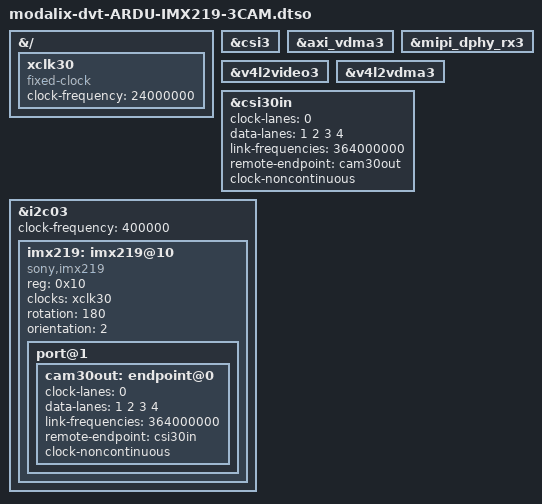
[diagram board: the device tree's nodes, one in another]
// SPDX-License-Identifier: (GPL-2.0+ OR MIT)
/*
 * Copyright (c) 2026 SiMa ai
 */

/dts-v1/;
/plugin/;

&{/} {
        xclk30: xclk30 {
                status = "okay";
                compatible = "fixed-clock";
                #clock-cells = <0>;
                clock-frequency = <24000000>;
        };
};

&csi3 {
    status = "okay";
};

&axi_vdma3 {
    status = "okay";
};

&mipi_dphy_rx3 {
    status = "okay";
};

&v4l2video3 {
    status = "okay";
};

&v4l2vdma3 {
    status = "okay";
};

&csi30in{
    clock-lanes = <0>;
    data-lanes = <1 2 3 4>;
    link-frequencies = /bits/ 64 <364000000>;
    remote-endpoint = <&cam30out>;
    clock-noncontinuous;
};

&i2c03 {
        status = "okay";
        clock-frequency = <400000>;
        #address-cells = <1>;
        #size-cells = <0>;

        imx219: imx219@10 {
                compatible = "sony,imx219";
                reg = <0x10>;

                clocks = <&xclk30>;
                clock-names = "xclk";

                rotation = <180>;
                orientation = <2>;

                port@1 {
                        cam30out: endpoint@0 {
                                clock-lanes = <0>;
                                data-lanes = <1 2 3 4>;
                                link-frequencies = /bits/ 64 <364000000>;
                                remote-endpoint = <&csi30in>;
                                clock-noncontinuous;
                        };
                };
        };
};
